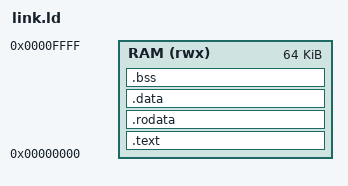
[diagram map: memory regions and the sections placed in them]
MEMORY { RAM (rwx) : ORIGIN = 0x00000000, LENGTH = 64K }
SECTIONS {
    .text : { *(.text.start) *(.text*) } > RAM
    .rodata : { *(.rodata*) *(.srodata*) } > RAM
    .data : { *(.data*) *(.sdata*) } > RAM
    .bss (NOLOAD) : { . = ALIGN(4); __bss_start = .; *(.bss*) *(.sbss*) *(COMMON) . = ALIGN(4); __bss_end = .; } > RAM
}
